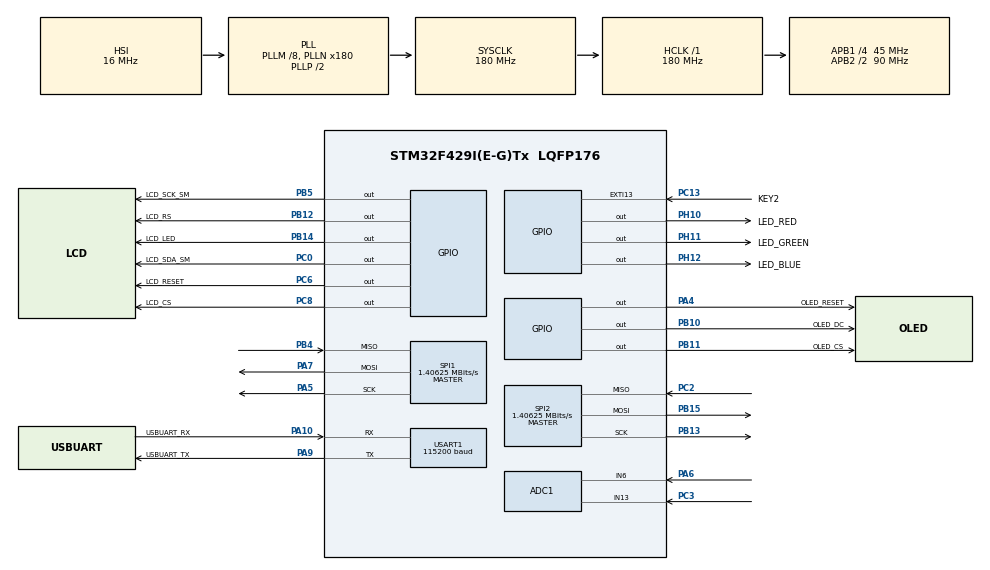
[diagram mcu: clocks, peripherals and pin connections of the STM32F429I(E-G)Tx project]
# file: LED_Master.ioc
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ADC1.Channel-0\#ChannelRegularConversion=ADC_CHANNEL_6
ADC1.Channel-1\#ChannelRegularConversion=ADC_CHANNEL_13
ADC1.Channel-2\#ChannelRegularConversion=ADC_CHANNEL_VREFINT
ADC1.Channel-3\#ChannelRegularConversion=ADC_CHANNEL_VREFINT
ADC1.ContinuousConvMode=ENABLE
ADC1.DMAContinuousRequests=ENABLE
ADC1.NbrOfConversion=4
ADC1.NbrOfConversionFlag=1
ADC1.Rank-0\#ChannelRegularConversion=1
ADC1.Rank-1\#ChannelRegularConversion=2
ADC1.Rank-2\#ChannelRegularConversion=3
ADC1.Rank-3\#ChannelRegularConversion=4
ADC1.SamplingTime-0\#ChannelRegularConversion=ADC_SAMPLETIME_84CYCLES
ADC1.SamplingTime-1\#ChannelRegularConversion=ADC_SAMPLETIME_84CYCLES
ADC1.SamplingTime-2\#ChannelRegularConversion=ADC_SAMPLETIME_84CYCLES
ADC1.SamplingTime-3\#ChannelRegularConversion=ADC_SAMPLETIME_84CYCLES
ADC1.ScanConvMode=ENABLE
ADC1.master=1
Dma.ADC1.3.Direction=DMA_PERIPH_TO_MEMORY
Dma.ADC1.3.FIFOMode=DMA_FIFOMODE_DISABLE
Dma.ADC1.3.Instance=DMA2_Stream4
Dma.ADC1.3.MemDataAlignment=DMA_MDATAALIGN_HALFWORD
Dma.ADC1.3.MemInc=DMA_MINC_ENABLE
Dma.ADC1.3.Mode=DMA_CIRCULAR
Dma.ADC1.3.PeriphDataAlignment=DMA_PDATAALIGN_HALFWORD
Dma.ADC1.3.PeriphInc=DMA_PINC_DISABLE
Dma.ADC1.3.Priority=DMA_PRIORITY_LOW
Dma.MEMTOMEM.2.Direction=DMA_MEMORY_TO_MEMORY
Dma.MEMTOMEM.2.FIFOMode=DMA_FIFOMODE_ENABLE
Dma.MEMTOMEM.2.FIFOThreshold=DMA_FIFO_THRESHOLD_FULL
Dma.MEMTOMEM.2.Instance=DMA2_Stream1
Dma.MEMTOMEM.2.MemBurst=DMA_MBURST_SINGLE
Dma.MEMTOMEM.2.MemDataAlignment=DMA_MDATAALIGN_BYTE
Dma.MEMTOMEM.2.MemInc=DMA_MINC_ENABLE
Dma.MEMTOMEM.2.Mode=DMA_NORMAL
Dma.MEMTOMEM.2.PeriphBurst=DMA_PBURST_SINGLE
Dma.MEMTOMEM.2.PeriphDataAlignment=DMA_PDATAALIGN_BYTE
Dma.MEMTOMEM.2.PeriphInc=DMA_PINC_ENABLE
Dma.MEMTOMEM.2.Priority=DMA_PRIORITY_LOW
Dma.Request0=USART1_RX
Dma.Request1=USART1_TX
Dma.Request2=MEMTOMEM
Dma.Request3=ADC1
Dma.Request4=SPI1_RX
Dma.Request5=SPI1_TX
Dma.Request6=SPI2_RX
Dma.Request7=SPI2_TX
Dma.SPI1_RX.4.Direction=DMA_PERIPH_TO_MEMORY
Dma.SPI1_RX.4.FIFOMode=DMA_FIFOMODE_DISABLE
Dma.SPI1_RX.4.Instance=DMA2_Stream0
Dma.SPI1_RX.4.MemDataAlignment=DMA_MDATAALIGN_BYTE
Dma.SPI1_RX.4.MemInc=DMA_MINC_ENABLE
Dma.SPI1_RX.4.Mode=DMA_NORMAL
Dma.SPI1_RX.4.PeriphDataAlignment=DMA_PDATAALIGN_BYTE
Dma.SPI1_RX.4.PeriphInc=DMA_PINC_DISABLE
Dma.SPI1_RX.4.Priority=DMA_PRIORITY_LOW
Dma.SPI1_TX.5.Direction=DMA_MEMORY_TO_PERIPH
Dma.SPI1_TX.5.FIFOMode=DMA_FIFOMODE_DISABLE
Dma.SPI1_TX.5.Instance=DMA2_Stream3
Dma.SPI1_TX.5.MemDataAlignment=DMA_MDATAALIGN_BYTE
Dma.SPI1_TX.5.MemInc=DMA_MINC_ENABLE
Dma.SPI1_TX.5.Mode=DMA_NORMAL
Dma.SPI1_TX.5.PeriphDataAlignment=DMA_PDATAALIGN_BYTE
Dma.SPI1_TX.5.PeriphInc=DMA_PINC_DISABLE
Dma.SPI1_TX.5.Priority=DMA_PRIORITY_LOW
Dma.SPI2_RX.6.Direction=DMA_PERIPH_TO_MEMORY
Dma.SPI2_RX.6.FIFOMode=DMA_FIFOMODE_DISABLE
Dma.SPI2_RX.6.Instance=DMA1_Stream3
Dma.SPI2_RX.6.MemDataAlignment=DMA_MDATAALIGN_BYTE
Dma.SPI2_RX.6.MemInc=DMA_MINC_ENABLE
Dma.SPI2_RX.6.Mode=DMA_NORMAL
Dma.SPI2_RX.6.PeriphDataAlignment=DMA_PDATAALIGN_BYTE
Dma.SPI2_RX.6.PeriphInc=DMA_PINC_DISABLE
Dma.SPI2_RX.6.Priority=DMA_PRIORITY_LOW
Dma.SPI2_TX.7.Direction=DMA_MEMORY_TO_PERIPH
Dma.SPI2_TX.7.FIFOMode=DMA_FIFOMODE_DISABLE
Dma.SPI2_TX.7.Instance=DMA1_Stream4
Dma.SPI2_TX.7.MemDataAlignment=DMA_MDATAALIGN_BYTE
Dma.SPI2_TX.7.MemInc=DMA_MINC_ENABLE
Dma.SPI2_TX.7.Mode=DMA_NORMAL
Dma.SPI2_TX.7.PeriphDataAlignment=DMA_PDATAALIGN_BYTE
Dma.SPI2_TX.7.PeriphInc=DMA_PINC_DISABLE
Dma.SPI2_TX.7.Priority=DMA_PRIORITY_LOW
Dma.USART1_RX.0.Direction=DMA_PERIPH_TO_MEMORY
Dma.USART1_RX.0.FIFOMode=DMA_FIFOMODE_DISABLE
Dma.USART1_RX.0.Instance=DMA2_Stream2
Dma.USART1_RX.0.MemDataAlignment=DMA_MDATAALIGN_BYTE
Dma.USART1_RX.0.MemInc=DMA_MINC_ENABLE
Dma.USART1_RX.0.Mode=DMA_NORMAL
Dma.USART1_RX.0.PeriphDataAlignment=DMA_PDATAALIGN_BYTE
Dma.USART1_RX.0.PeriphInc=DMA_PINC_DISABLE
Dma.USART1_RX.0.Priority=DMA_PRIORITY_LOW
Dma.USART1_TX.1.Direction=DMA_MEMORY_TO_PERIPH
Dma.USART1_TX.1.FIFOMode=DMA_FIFOMODE_ENABLE
Dma.USART1_TX.1.FIFOThreshold=DMA_FIFO_THRESHOLD_FULL
Dma.USART1_TX.1.Instance=DMA2_Stream7
Dma.USART1_TX.1.MemBurst=DMA_MBURST_SINGLE
Dma.USART1_TX.1.MemDataAlignment=DMA_MDATAALIGN_BYTE
Dma.USART1_TX.1.MemInc=DMA_MINC_ENABLE
Dma.USART1_TX.1.Mode=DMA_NORMAL
Dma.USART1_TX.1.PeriphBurst=DMA_PBURST_SINGLE
Dma.USART1_TX.1.PeriphDataAlignment=DMA_PDATAALIGN_BYTE
Dma.USART1_TX.1.PeriphInc=DMA_PINC_DISABLE
Dma.USART1_TX.1.Priority=DMA_PRIORITY_LOW
Mcu.Family=STM32F4
Mcu.Name=STM32F429I(E-G)Tx
Mcu.Package=LQFP176
Mcu.UserConstants=Print_COM,$$_USART1_IP_HANDLE_$$;OLED_SPI,$$_SPI1_IP_HANDLE_$$;LCD_SPI,$$_SPI2_IP_HANDLE_$$
NVIC.DMA1_Stream3_IRQn=true\:0\:0\:false\:false\:true\:false\:true\:true
NVIC.DMA1_Stream4_IRQn=true\:0\:0\:false\:false\:true\:false\:true\:true
NVIC.DMA2_Stream0_IRQn=true\:0\:0\:true\:false\:true\:true\:true\:true
NVIC.DMA2_Stream2_IRQn=true\:15\:0\:true\:false\:true\:false\:true\:true
NVIC.DMA2_Stream3_IRQn=true\:0\:0\:false\:false\:true\:false\:true\:true
NVIC.DMA2_Stream4_IRQn=true\:0\:0\:false\:false\:true\:false\:true\:true
NVIC.DMA2_Stream7_IRQn=true\:15\:0\:true\:false\:true\:false\:true\:true
NVIC.EXTI15_10_IRQn=true\:14\:0\:true\:false\:true\:true\:true\:true
NVIC.PriorityGroup=NVIC_PRIORITYGROUP_4
NVIC.SPI1_IRQn=true\:0\:0\:false\:false\:true\:true\:true\:true
NVIC.SPI2_IRQn=true\:0\:0\:false\:false\:true\:true\:true\:true
NVIC.TIM3_IRQn=true\:1\:0\:true\:false\:true\:true\:true\:true
NVIC.TIM4_IRQn=true\:5\:0\:true\:false\:true\:true\:true\:true
NVIC.USART1_IRQn=true\:14\:0\:true\:false\:true\:true\:true\:true
PA10.GPIO_Label=USBUART_RX
PA10.Mode=Asynchronous
PA10.Signal=USART1_RX
PA4.GPIO_Label=OLED_RESET
PA4.GPIO_PuPd=GPIO_PULLUP
PA4.GPIO_Speed=GPIO_SPEED_FREQ_VERY_HIGH
PA4.Signal=GPIO_Output
PA5.Mode=Full_Duplex_Master
PA5.Signal=SPI1_SCK
PA6.Signal=ADCx_IN6
PA7.Mode=Full_Duplex_Master
PA7.Signal=SPI1_MOSI
PA9.GPIO_Label=USBUART_TX
PA9.Mode=Asynchronous
PA9.Signal=USART1_TX
PB10.GPIO_Label=OLED_DC
PB10.GPIO_PuPd=GPIO_PULLUP
PB10.GPIO_Speed=GPIO_SPEED_FREQ_VERY_HIGH
PB10.Signal=GPIO_Output
PB11.GPIO_Label=OLED_CS
PB11.GPIO_PuPd=GPIO_PULLUP
PB11.GPIO_Speed=GPIO_SPEED_FREQ_VERY_HIGH
PB11.Signal=GPIO_Output
PB12.GPIO_Label=LCD_RS
PB12.GPIO_PuPd=GPIO_PULLUP
PB12.GPIO_Speed=GPIO_SPEED_FREQ_VERY_HIGH
PB12.Signal=GPIO_Output
PB13.Mode=Full_Duplex_Master
PB13.Signal=SPI2_SCK
PB14.GPIO_Label=LCD_LED
PB14.GPIO_PuPd=GPIO_PULLUP
PB14.GPIO_Speed=GPIO_SPEED_FREQ_VERY_HIGH
PB14.Signal=GPIO_Output
PB15.Mode=Full_Duplex_Master
PB15.Signal=SPI2_MOSI
PB4.Mode=Full_Duplex_Master
PB4.Signal=SPI1_MISO
PB5.GPIO_Label=LCD_SCK_SM
PB5.GPIO_PuPd=GPIO_PULLUP
PB5.GPIO_Speed=GPIO_SPEED_FREQ_VERY_HIGH
PB5.Signal=GPIO_Output
PC0.GPIO_Label=LCD_SDA_SM
PC0.GPIO_PuPd=GPIO_PULLUP
PC0.GPIO_Speed=GPIO_SPEED_FREQ_VERY_HIGH
PC0.Signal=GPIO_Output
PC13.GPIO_Label=KEY2
PC13.Signal=GPXTI13
PC2.Mode=Full_Duplex_Master
PC2.Signal=SPI2_MISO
PC3.Signal=ADCx_IN13
PC6.GPIO_Label=LCD_RESET
PC6.GPIO_PuPd=GPIO_PULLUP
PC6.GPIO_Speed=GPIO_SPEED_FREQ_VERY_HIGH
PC6.Signal=GPIO_Output
PC8.GPIO_Label=LCD_CS
PC8.GPIO_ModeDefaultOutputPP=GPIO_MODE_OUTPUT_PP
PC8.GPIO_PuPd=GPIO_PULLUP
PC8.GPIO_Speed=GPIO_SPEED_FREQ_VERY_HIGH
PC8.Signal=GPIO_Output
PH0/OSC_IN.Mode=HSE-External-Oscillator
PH0/OSC_IN.Signal=RCC_OSC_IN
PH1/OSC_OUT.Mode=HSE-External-Oscillator
PH1/OSC_OUT.Signal=RCC_OSC_OUT
PH10.GPIO_Label=LED_RED
PH10.GPIO_Speed=GPIO_SPEED_FREQ_LOW
PH10.PinState=GPIO_PIN_SET
PH10.Signal=GPIO_Output
PH11.GPIO_Label=LED_GREEN
PH11.PinState=GPIO_PIN_SET
PH11.Signal=GPIO_Output
PH12.GPIO_Label=LED_BLUE
PH12.PinState=GPIO_PIN_SET
PH12.Signal=GPIO_Output
ProjectManager.HeapSize=0x200
ProjectManager.StackSize=0x400
ProjectManager.TargetToolchain=STM32CubeIDE
RCC.48MHZClocksFreq_Value=90000000
RCC.AHBFreq_Value=180000000
RCC.APB1CLKDivider=RCC_HCLK_DIV4
RCC.APB1Freq_Value=45000000
RCC.APB1TimFreq_Value=90000000
RCC.APB2CLKDivider=RCC_HCLK_DIV2
RCC.APB2Freq_Value=90000000
RCC.APB2TimFreq_Value=180000000
RCC.CortexFreq_Value=180000000
RCC.HCLKFreq_Value=180000000
RCC.HSE_VALUE=25000000
RCC.HSI_VALUE=16000000
RCC.LSE_VALUE=32768
RCC.PLLM=8
RCC.PLLN=180
RCC.SYSCLKFreq_VALUE=180000000
RCC.SYSCLKSource=RCC_SYSCLKSOURCE_PLLCLK
RCC.VCOOutputFreq_Value=360000000
SH.ADCx_IN13.0=ADC1_IN13,IN13
SH.ADCx_IN6.0=ADC1_IN6,IN6
SPI1.BaudRatePrescaler=SPI_BAUDRATEPRESCALER_64
SPI1.CLKPolarity=SPI_POLARITY_HIGH
SPI1.CalculateBaudRate=1.40625 MBits/s
SPI1.Direction=SPI_DIRECTION_2LINES
SPI1.Mode=SPI_MODE_MASTER
SPI1.VirtualType=VM_MASTER
SPI2.BaudRatePrescaler=SPI_BAUDRATEPRESCALER_32
SPI2.CLKPhase=SPI_PHASE_1EDGE
SPI2.CLKPolarity=SPI_POLARITY_HIGH
SPI2.CalculateBaudRate=1.40625 MBits/s
SPI2.Direction=SPI_DIRECTION_2LINES
SPI2.Mode=SPI_MODE_MASTER
SPI2.VirtualType=VM_MASTER
TIM3.Period=10000-1
TIM3.Prescaler=9000-1
TIM4.Period=100-1
TIM4.Prescaler=900-1
USART1.BaudRate=115200
USART1.VirtualMode=VM_ASYNC
VP_ADC1_TempSens_Input.Mode=IN-TempSens
VP_ADC1_Vref_Input.Mode=IN-Vrefint
VP_TIM3_VS_ClockSourceINT.Mode=Internal
VP_TIM4_VS_ClockSourceINT.Mode=Internal
board=custom

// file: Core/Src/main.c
/* USER CODE BEGIN Header */
/**
  ******************************************************************************
  * @file           : main.c
  * @brief          : Main program body
  ******************************************************************************
  * @attention
  *
  * Copyright (c) 2025 STMicroelectronics.
  * All rights reserved.
  *
  * This software is licensed under terms that can be found in the LICENSE file
  * in the root directory of this software component.
  * If no LICENSE file comes with this software, it is provided AS-IS.
  *
  ******************************************************************************
  */
/* USER CODE END Header */
#include "main.h"
#include "adc.h"
#include "dma.h"
#include "spi.h"
#include "tim.h"
#include "usart.h"
#include "gpio.h"

/* USER CODE BEGIN Includes */
#include "task_bsp.h"
/* USER CODE END Includes */

void SystemClock_Config(void);

int main(void)
{

  /* MCU Configuration--------------------------------------------------------*/

  /* Reset of all peripherals, Initializes the Flash interface and the Systick. */
  HAL_Init();

  /* Configure the system clock */
  SystemClock_Config();

  /* Initialize all configured peripherals */
  MX_GPIO_Init();
  MX_DMA_Init();
  MX_USART1_UART_Init();
  MX_TIM4_Init();
  MX_TIM3_Init();
  MX_ADC1_Init();
  MX_SPI1_Init();
  MX_SPI2_Init();
  /* USER CODE BEGIN 2 */
  OS_Init();
  /* USER CODE END 2 */

  /* Infinite loop */
  /* USER CODE BEGIN WHILE */
  while (1)
  {
	  Start_OS();
    /* USER CODE END WHILE */

  }
}

void SystemClock_Config(void)
{
  RCC_OscInitTypeDef RCC_OscInitStruct = {0};
  RCC_ClkInitTypeDef RCC_ClkInitStruct = {0};

  /** Configure the main internal regulator output voltage
  */
  __HAL_RCC_PWR_CLK_ENABLE();
  __HAL_PWR_VOLTAGESCALING_CONFIG(PWR_REGULATOR_VOLTAGE_SCALE1);

  /** Initializes the RCC Oscillators according to the specified parameters
  * in the RCC_OscInitTypeDef structure.
  */
  RCC_OscInitStruct.OscillatorType = RCC_OSCILLATORTYPE_HSI;
  RCC_OscInitStruct.HSIState = RCC_HSI_ON;
  RCC_OscInitStruct.HSICalibrationValue = RCC_HSICALIBRATION_DEFAULT;
  RCC_OscInitStruct.PLL.PLLState = RCC_PLL_ON;
  RCC_OscInitStruct.PLL.PLLSource = RCC_PLLSOURCE_HSI;
  RCC_OscInitStruct.PLL.PLLM = 8;
  RCC_OscInitStruct.PLL.PLLN = 180;
  RCC_OscInitStruct.PLL.PLLP = RCC_PLLP_DIV2;
  RCC_OscInitStruct.PLL.PLLQ = 4;
  if (HAL_RCC_OscConfig(&RCC_OscInitStruct) != HAL_OK)
  {
    Error_Handler();
  }

  /** Activate the Over-Drive mode
  */
  if (HAL_PWREx_EnableOverDrive() != HAL_OK)
  {
    Error_Handler();
  }

  /** Initializes the CPU, AHB and APB buses clocks
  */
  RCC_ClkInitStruct.ClockType = RCC_CLOCKTYPE_HCLK|RCC_CLOCKTYPE_SYSCLK
                              |RCC_CLOCKTYPE_PCLK1|RCC_CLOCKTYPE_PCLK2;
  RCC_ClkInitStruct.SYSCLKSource = RCC_SYSCLKSOURCE_PLLCLK;
  RCC_ClkInitStruct.AHBCLKDivider = RCC_SYSCLK_DIV1;
  RCC_ClkInitStruct.APB1CLKDivider = RCC_HCLK_DIV4;
  RCC_ClkInitStruct.APB2CLKDivider = RCC_HCLK_DIV2;

  if (HAL_RCC_ClockConfig(&RCC_ClkInitStruct, FLASH_LATENCY_5) != HAL_OK)
  {
    Error_Handler();
  }
}

void Error_Handler(void)
{
  __disable_irq();
  while (1)
  {
  }
}
